# STM32F101 register map
File version: 1.1
CPU: CM3 r1p1, little endian, no MPU, no FPU, 4 interrupt priority bits
Registers are 32-bit, read-write, reset 0x0 unless marked. A register's access mark holds for its fields unless they carry their own. Offsets are from the block's base; [hi:lo] are bit positions; lines under a group give offsets from that group; {n}, {i} and the like mark numbered series.

## OTG_FS_HOST — USB on the go full speed
Base 0x50000400
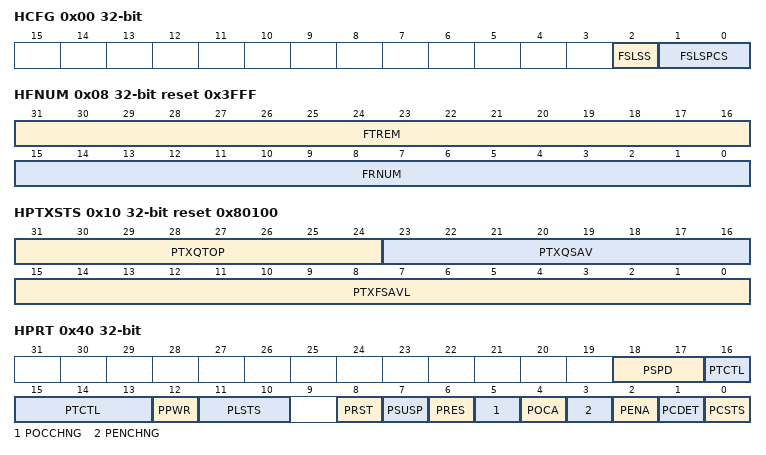
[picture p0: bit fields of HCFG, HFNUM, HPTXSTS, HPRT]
0x00 HCFG — OTG_FS host configuration register (OTG_FS_HCFG)
  [2] FSLSS — FS- and LS-only support
  [1:0] FSLSPCS — FS/LS PHY clock select
0x04 HFIR reset 0xEA60 — OTG_FS Host frame interval register
  [15:0] FRIVL — Frame interval
0x08 HFNUM ro reset 0x3FFF — OTG_FS host frame number/frame time remaining register (OTG_FS_HFNUM)
  [31:16] FTREM — Frame time remaining
  [15:0] FRNUM — Frame number
0x10 HPTXSTS access per field reset 0x80100 — OTG_FS_Host periodic transmit FIFO/queue status register (OTG_FS_HPTXSTS)
  [31:24] PTXQTOP ro — Top of the periodic transmit request queue
  [23:16] PTXQSAV ro — Periodic transmit request queue space available
  [15:0] PTXFSAVL rw — Periodic transmit data FIFO space available
0x14 HAINT ro — OTG_FS Host all channels interrupt register
  [15:0] HAINT — Channel interrupts
0x18 HAINTMSK — OTG_FS host all channels interrupt mask register
  [15:0] HAINTM — Channel interrupt mask
0x40 HPRT access per field — OTG_FS host port control and status register (OTG_FS_HPRT)
  [18:17] PSPD ro — Port speed
  [16:13] PTCTL rw — Port test control
  [12] PPWR rw — Port power
  [11:10] PLSTS ro — Port line status
  [8] PRST rw — Port reset
  [7] PSUSP rw — Port suspend
  [6] PRES rw — Port resume
  [5] POCCHNG rw — Port overcurrent change
  [4] POCA ro — Port overcurrent active
  [3] PENCHNG rw — Port enable/disable change
  [2] PENA rw — Port enable
  [1] PCDET rw — Port connect detected
  [0] PCSTS ro — Port connect status
{0x100+0x20*i} HC{i} (i=0..7) group — Host channel
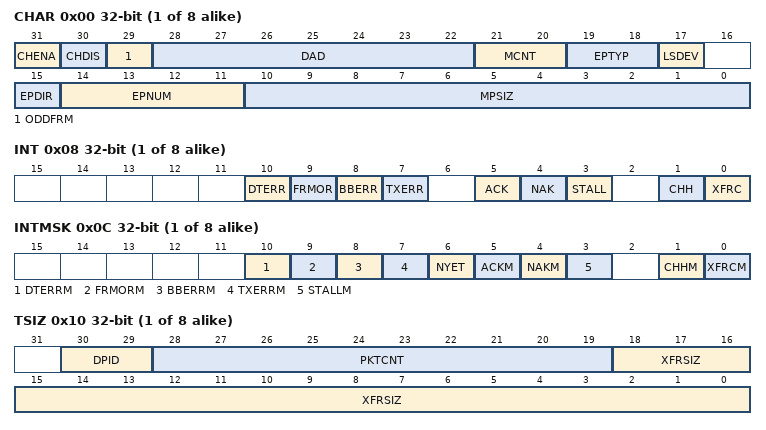
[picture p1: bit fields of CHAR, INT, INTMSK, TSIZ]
  0x00 CHAR — OTG_FS host channel-0 characteristics register (OTG_FS_HCCHAR0)
    [31] CHENA — Channel enable
    [30] CHDIS — Channel disable
    [29] ODDFRM — Odd frame
    [28:22] DAD — Device address
    [21:20] MCNT — Multicount
    [19:18] EPTYP — Endpoint type
    [17] LSDEV — Low-speed device
    [15] EPDIR — Endpoint direction
    [14:11] EPNUM — Endpoint number
    [10:0] MPSIZ — Maximum packet size
  0x08 INT — OTG_FS host channel-0 interrupt register (OTG_FS_HCINT0)
    [10] DTERR — Data toggle error
    [9] FRMOR — Frame overrun
    [8] BBERR — Babble error
    [7] TXERR — Transaction error
    [5] ACK — ACK response received/transmitted interrupt
    [4] NAK — NAK response received interrupt
    [3] STALL — STALL response received interrupt
    [1] CHH — Channel halted
    [0] XFRC — Transfer completed
  0x0C INTMSK — OTG_FS host channel-0 mask register (OTG_FS_HCINTMSK0)
    [10] DTERRM — Data toggle error mask
    [9] FRMORM — Frame overrun mask
    [8] BBERRM — Babble error mask
    [7] TXERRM — Transaction error mask
    [6] NYET — response received interrupt mask
    [5] ACKM — ACK response received/transmitted interrupt mask
    [4] NAKM — NAK response received interrupt mask
    [3] STALLM — STALL response received interrupt mask
    [1] CHHM — Channel halted mask
    [0] XFRCM — Transfer completed mask
  0x10 TSIZ — OTG_FS host channel-0 transfer size register
    [30:29] DPID — Data PID
    [28:19] PKTCNT — Packet count
    [18:0] XFRSIZ — Transfer size

## OTG_FS_PWRCLK — USB on the go full speed
Base 0x50000E00
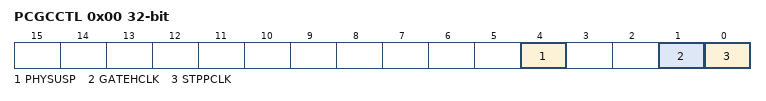
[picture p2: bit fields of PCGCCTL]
0x00 PCGCCTL — OTG_FS power and clock gating control register
  [4] PHYSUSP — PHY Suspended
  [1] GATEHCLK
  [0] STPPCLK — Stop PHY clock

## Ethernet_MMC — Ethernet: MAC management counters
Base 0x40028100
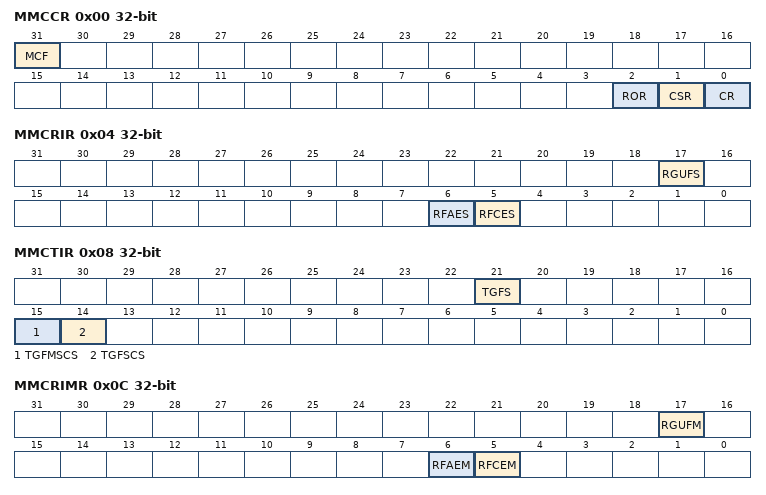
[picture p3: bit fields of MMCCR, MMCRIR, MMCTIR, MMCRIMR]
0x00 MMCCR — Ethernet MMC control register (ETH_MMCCR)
  [31] MCF — MMC counter freeze
  [2] ROR — Reset on read
  [1] CSR — Counter stop rollover
  [0] CR — Counter reset
0x04 MMCRIR — Ethernet MMC receive interrupt register (ETH_MMCRIR)
  [17] RGUFS — Received Good Unicast Frames Status
  [6] RFAES — Received frames alignment error status
  [5] RFCES — Received frames CRC error status
0x08 MMCTIR — Ethernet MMC transmit interrupt register (ETH_MMCTIR)
  [21] TGFS — Transmitted good frames status
  [15] TGFMSCS — Transmitted good frames more single collision status
  [14] TGFSCS — Transmitted good frames single collision status
0x0C MMCRIMR — Ethernet MMC receive interrupt mask register (ETH_MMCRIMR)
  [17] RGUFM — Received good unicast frames mask
  [6] RFAEM — Received frames alignment error mask
  [5] RFCEM — Received frame CRC error mask
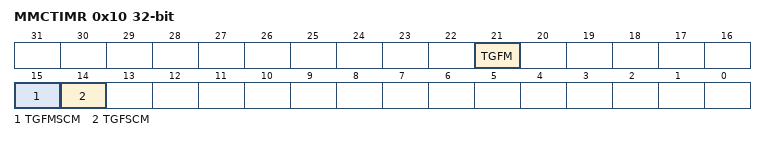
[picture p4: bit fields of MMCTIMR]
0x10 MMCTIMR — Ethernet MMC transmit interrupt mask register (ETH_MMCTIMR)
  [21] TGFM — Transmitted good frames mask
  [15] TGFMSCM — Transmitted good frames more single collision mask
  [14] TGFSCM — Transmitted good frames single collision mask
0x4C MMCTGFSCCR ro — Ethernet MMC transmitted good frames after a single collision counter
  [31:0] TGFSCC — Transmitted good frames after a single collision counter
0x50 MMCTGFMSCCR ro — Ethernet MMC transmitted good frames after more than a single collision
  [31:0] TGFMSCC — Transmitted good frames after more than a single collision counter
0x68 MMCTGFCR ro — Ethernet MMC transmitted good frames counter register
  [31:0] TGFC — Transmitted good frames counter
0x94 MMCRFCECR ro — Ethernet MMC received frames with CRC error counter register
  [31:0] RFCFC — Received frames with CRC error counter
0x98 MMCRFAECR ro — Ethernet MMC received frames with alignment error counter register
  [31:0] RFAEC — Received frames with alignment error counter
0xC4 MMCRGUFCR ro — MMC received good unicast frames counter register
  [31:0] RGUFC — Received good unicast frames counter
